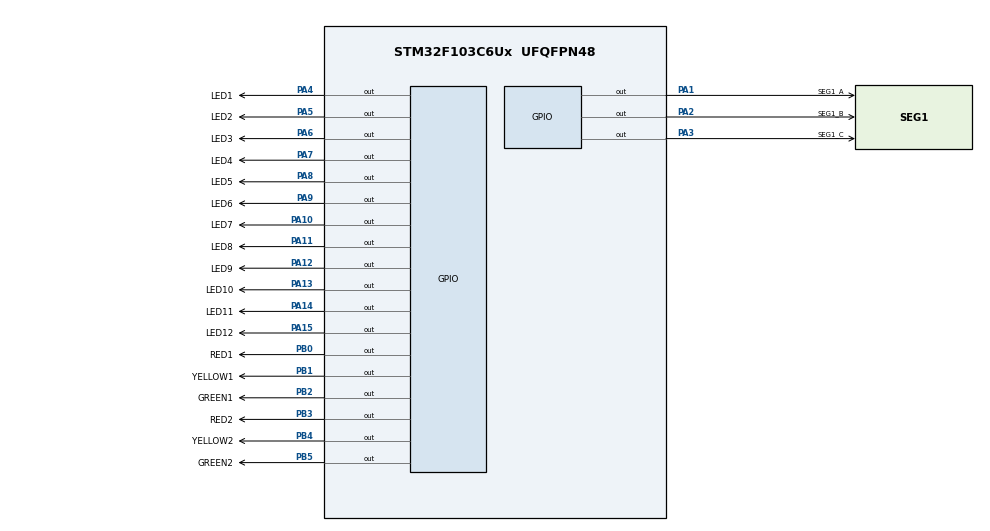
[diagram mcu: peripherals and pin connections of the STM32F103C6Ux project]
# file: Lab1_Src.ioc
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Mcu.Family=STM32F1
Mcu.Name=STM32F103C6Ux
Mcu.Package=UFQFPN48
NVIC.PriorityGroup=NVIC_PRIORITYGROUP_4
PA1.GPIO_Label=SEG1_A
PA1.Signal=GPIO_Output
PA10.GPIO_Label=LED7
PA10.Signal=GPIO_Output
PA11.GPIO_Label=LED8
PA11.Signal=GPIO_Output
PA12.GPIO_Label=LED9
PA12.Signal=GPIO_Output
PA13.GPIO_Label=LED10
PA13.Signal=GPIO_Output
PA14.GPIO_Label=LED11
PA14.Signal=GPIO_Output
PA15.GPIO_Label=LED12
PA15.Signal=GPIO_Output
PA2.GPIO_Label=SEG1_B
PA2.Signal=GPIO_Output
PA3.GPIO_Label=SEG1_C
PA3.Signal=GPIO_Output
PA4.GPIO_Label=LED1
PA4.Signal=GPIO_Output
PA5.GPIO_Label=LED2
PA5.Signal=GPIO_Output
PA6.GPIO_Label=LED3
PA6.Signal=GPIO_Output
PA7.GPIO_Label=LED4
PA7.Signal=GPIO_Output
PA8.GPIO_Label=LED5
PA8.Signal=GPIO_Output
PA9.GPIO_Label=LED6
PA9.Signal=GPIO_Output
PB0.GPIO_Label=RED1
PB0.Signal=GPIO_Output
PB1.GPIO_Label=YELLOW1
PB1.Signal=GPIO_Output
PB2.GPIO_Label=GREEN1
PB2.Signal=GPIO_Output
PB3.GPIO_Label=RED2
PB3.Signal=GPIO_Output
PB4.GPIO_Label=YELLOW2
PB4.Signal=GPIO_Output
PB5.GPIO_Label=GREEN2
PB5.Signal=GPIO_Output
ProjectManager.HeapSize=0x200
ProjectManager.StackSize=0x400
ProjectManager.TargetToolchain=STM32CubeIDE
RCC.APB1Freq_Value=8000000
RCC.APB2Freq_Value=8000000
VP_SYS_VS_ND.Mode=No_Debug
board=custom

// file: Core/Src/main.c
/* USER CODE BEGIN Header */
/**
  ******************************************************************************
  * @file           : main.c
  * @brief          : Main program body
  ******************************************************************************
  * @attention
  *
  * <h2><center>&copy; Copyright (c) 2024 STMicroelectronics.
  * All rights reserved.</center></h2>
  *
  * This software component is licensed by ST under BSD 3-Clause license,
  * the "License"; You may not use this file except in compliance with the
  * License. You may obtain a copy of the License at:
  *                        opensource.org/licenses/BSD-3-Clause
  *
  ******************************************************************************
  */
/* USER CODE END Header */
#include "main.h"

/* USER CODE BEGIN Includes */
#include "Lab1_Ex6to10.h"
/* USER CODE END Includes */

void SystemClock_Config(void);
static void MX_GPIO_Init(void);

int main(void)
{

  /* MCU Configuration--------------------------------------------------------*/

  /* Reset of all peripherals, Initializes the Flash interface and the Systick. */
  HAL_Init();

  /* Configure the system clock */
  SystemClock_Config();

  /* Initialize all configured peripherals */
  MX_GPIO_Init();

  /* Infinite loop */
  /* USER CODE BEGIN WHILE */
  Lab1_Ex6To10_Init();
  while (1)
  {
	  Lab1_Ex10_AutoRun();
	  //Lab1_Ex10_EnterTime(9, 55, 30);
	  HAL_Delay(10);
    /* USER CODE END WHILE */

  }
}

void SystemClock_Config(void)
{
  RCC_OscInitTypeDef RCC_OscInitStruct = {0};
  RCC_ClkInitTypeDef RCC_ClkInitStruct = {0};

  /** Initializes the RCC Oscillators according to the specified parameters
  * in the RCC_OscInitTypeDef structure.
  */
  RCC_OscInitStruct.OscillatorType = RCC_OSCILLATORTYPE_HSI;
  RCC_OscInitStruct.HSIState = RCC_HSI_ON;
  RCC_OscInitStruct.HSICalibrationValue = RCC_HSICALIBRATION_DEFAULT;
  RCC_OscInitStruct.PLL.PLLState = RCC_PLL_NONE;
  if (HAL_RCC_OscConfig(&RCC_OscInitStruct) != HAL_OK)
  {
    Error_Handler();
  }
  /** Initializes the CPU, AHB and APB buses clocks
  */
  RCC_ClkInitStruct.ClockType = RCC_CLOCKTYPE_HCLK|RCC_CLOCKTYPE_SYSCLK
                              |RCC_CLOCKTYPE_PCLK1|RCC_CLOCKTYPE_PCLK2;
  RCC_ClkInitStruct.SYSCLKSource = RCC_SYSCLKSOURCE_HSI;
  RCC_ClkInitStruct.AHBCLKDivider = RCC_SYSCLK_DIV1;
  RCC_ClkInitStruct.APB1CLKDivider = RCC_HCLK_DIV1;
  RCC_ClkInitStruct.APB2CLKDivider = RCC_HCLK_DIV1;

  if (HAL_RCC_ClockConfig(&RCC_ClkInitStruct, FLASH_LATENCY_0) != HAL_OK)
  {
    Error_Handler();
  }
}

static void MX_GPIO_Init(void)
{
  GPIO_InitTypeDef GPIO_InitStruct = {0};

  /* GPIO Ports Clock Enable */
  __HAL_RCC_GPIOA_CLK_ENABLE();
  __HAL_RCC_GPIOB_CLK_ENABLE();

  /*Configure GPIO pin Output Level */
  HAL_GPIO_WritePin(GPIOA, SEG1_A_Pin|SEG1_B_Pin|SEG1_C_Pin|LED1_Pin
                          |LED2_Pin|LED3_Pin|LED4_Pin|LED5_Pin
                          |LED6_Pin|LED7_Pin|LED8_Pin|LED9_Pin
                          |LED10_Pin|LED11_Pin|LED12_Pin, GPIO_PIN_RESET);

  /*Configure GPIO pin Output Level */
  HAL_GPIO_WritePin(GPIOB, RED1_Pin|YELLOW1_Pin|GREEN1_Pin|RED2_Pin
                          |YELLOW2_Pin|GREEN2_Pin, GPIO_PIN_RESET);

  /*Configure GPIO pins : SEG1_A_Pin SEG1_B_Pin SEG1_C_Pin LED1_Pin
                           LED2_Pin LED3_Pin LED4_Pin LED5_Pin
                           LED6_Pin LED7_Pin LED8_Pin LED9_Pin
                           LED10_Pin LED11_Pin LED12_Pin */
  GPIO_InitStruct.Pin = SEG1_A_Pin|SEG1_B_Pin|SEG1_C_Pin|LED1_Pin
                          |LED2_Pin|LED3_Pin|LED4_Pin|LED5_Pin
                          |LED6_Pin|LED7_Pin|LED8_Pin|LED9_Pin
                          |LED10_Pin|LED11_Pin|LED12_Pin;
  GPIO_InitStruct.Mode = GPIO_MODE_OUTPUT_PP;
  GPIO_InitStruct.Pull = GPIO_NOPULL;
  GPIO_InitStruct.Speed = GPIO_SPEED_FREQ_LOW;
  HAL_GPIO_Init(GPIOA, &GPIO_InitStruct);

  /*Configure GPIO pins : RED1_Pin YELLOW1_Pin GREEN1_Pin RED2_Pin
                           YELLOW2_Pin GREEN2_Pin */
  GPIO_InitStruct.Pin = RED1_Pin|YELLOW1_Pin|GREEN1_Pin|RED2_Pin
                          |YELLOW2_Pin|GREEN2_Pin;
  GPIO_InitStruct.Mode = GPIO_MODE_OUTPUT_PP;
  GPIO_InitStruct.Pull = GPIO_NOPULL;
  GPIO_InitStruct.Speed = GPIO_SPEED_FREQ_LOW;
  HAL_GPIO_Init(GPIOB, &GPIO_InitStruct);

}

void Error_Handler(void)
{
  __disable_irq();
  while (1)
  {
  }
}

/************************ (C) COPYRIGHT STMicroelectronics *****END OF FILE****/
